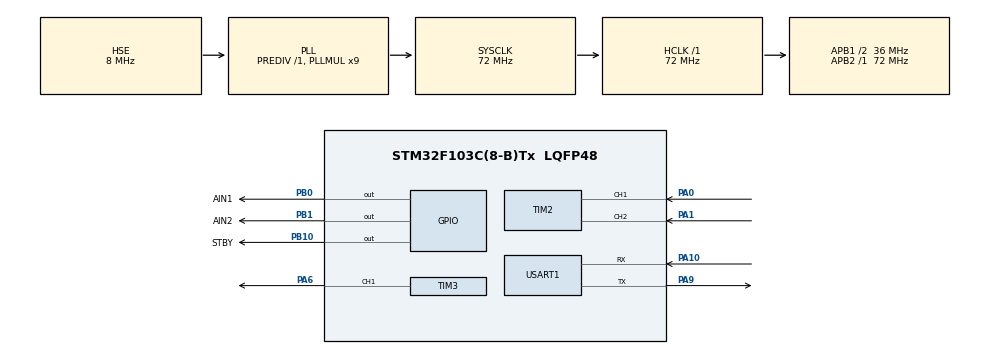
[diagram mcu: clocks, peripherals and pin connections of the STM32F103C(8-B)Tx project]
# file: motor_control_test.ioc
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Mcu.Family=STM32F1
Mcu.Name=STM32F103C(8-B)Tx
Mcu.Package=LQFP48
NVIC.PriorityGroup=NVIC_PRIORITYGROUP_4
PA0-WKUP.Signal=S_TIM2_CH1_ETR
PA1.Signal=S_TIM2_CH2
PA10.Mode=Asynchronous
PA10.Signal=USART1_RX
PA13.Mode=Serial_Wire
PA13.Signal=SYS_JTMS-SWDIO
PA14.Mode=Serial_Wire
PA14.Signal=SYS_JTCK-SWCLK
PA6.Signal=S_TIM3_CH1
PA9.Mode=Asynchronous
PA9.Signal=USART1_TX
PB0.GPIO_Label=AIN1
PB0.Signal=GPIO_Output
PB1.GPIO_Label=AIN2
PB1.Signal=GPIO_Output
PB10.GPIO_Label=STBY
PB10.Signal=GPIO_Output
PD0-OSC_IN.Mode=HSE-External-Oscillator
PD0-OSC_IN.Signal=RCC_OSC_IN
PD1-OSC_OUT.Mode=HSE-External-Oscillator
PD1-OSC_OUT.Signal=RCC_OSC_OUT
ProjectManager.HeapSize=0x200
ProjectManager.StackSize=0x400
ProjectManager.TargetToolchain=CMake
RCC.AHBFreq_Value=72000000
RCC.APB1CLKDivider=RCC_HCLK_DIV2
RCC.APB1Freq_Value=36000000
RCC.APB1TimFreq_Value=72000000
RCC.APB2Freq_Value=72000000
RCC.APB2TimFreq_Value=72000000
RCC.HCLKFreq_Value=72000000
RCC.PLLMUL=RCC_PLL_MUL9
RCC.PLLSourceVirtual=RCC_PLLSOURCE_HSE
RCC.SYSCLKFreq_VALUE=72000000
RCC.SYSCLKSource=RCC_SYSCLKSOURCE_PLLCLK
RCC.USBFreq_Value=72000000
SH.S_TIM2_CH1_ETR.0=TIM2_CH1,Encoder_Interface
SH.S_TIM2_CH2.0=TIM2_CH2,Encoder_Interface
SH.S_TIM3_CH1.0=TIM3_CH1,PWM Generation1 CH1
TIM2.EncoderMode=TIM_ENCODERMODE_TI2
TIM2.IC1Filter=10
TIM2.IC2Filter=10
TIM3.Channel-PWM\ Generation1\ CH1=TIM_CHANNEL_1
TIM3.Period=999
TIM3.Prescaler=71
USART1.VirtualMode=VM_ASYNC
VP_TIM3_VS_ClockSourceINT.Mode=Internal
board=custom

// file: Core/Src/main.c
/* USER CODE BEGIN Header */
/**
  ******************************************************************************
  * @file           : main.c
  * @brief          : Main program body
  ******************************************************************************
  * @attention
  *
  * Copyright (c) 2026 STMicroelectronics.
  * All rights reserved.
  *
  * This software is licensed under terms that can be found in the LICENSE file
  * in the root directory of this software component.
  * If no LICENSE file comes with this software, it is provided AS-IS.
  *
  ******************************************************************************
  */
/* USER CODE END Header */
#include "main.h"

#include <stdio.h>

#include "tim.h"
#include "usart.h"
#include "gpio.h"

/* USER CODE BEGIN PV */
 int16_t last_cnt = 0;

int16_t now_cnt;
int16_t delta;
/* USER CODE BEGIN PV */
int16_t  speed       = 0;    // 当前速度 (RPM)
uint8_t  pwm         = 0;    // PWM占空比 (0-100)
int16_t  targetSpeed = 1500; // 目标速度 (RPM)
uint32_t counter     = 0;    // 计数器值
char buf[20];               // sprintf格式化缓冲
/* USER CODE END PV */

void SystemClock_Config(void);

/* USER CODE BEGIN 0 */
/* USER CODE BEGIN 0 */

/* USER CODE END 0 */

int main(void)
{

  /* MCU Configuration--------------------------------------------------------*/

  /* Reset of all peripherals, Initializes the Flash interface and the Systick. */
  HAL_Init();

  /* Configure the system clock */
  SystemClock_Config();

  /* Initialize all configured peripherals */
  MX_GPIO_Init();
  MX_TIM2_Init();
  MX_TIM3_Init();
  MX_USART1_UART_Init();

  /* Infinite loop */
  while (1)
  {

  }
}

void SystemClock_Config(void)
{
  RCC_OscInitTypeDef RCC_OscInitStruct = {0};
  RCC_ClkInitTypeDef RCC_ClkInitStruct = {0};

  /** Initializes the RCC Oscillators according to the specified parameters
  * in the RCC_OscInitTypeDef structure.
  */
  RCC_OscInitStruct.OscillatorType = RCC_OSCILLATORTYPE_HSE;
  RCC_OscInitStruct.HSEState = RCC_HSE_ON;
  RCC_OscInitStruct.HSEPredivValue = RCC_HSE_PREDIV_DIV1;
  RCC_OscInitStruct.HSIState = RCC_HSI_ON;
  RCC_OscInitStruct.PLL.PLLState = RCC_PLL_ON;
  RCC_OscInitStruct.PLL.PLLSource = RCC_PLLSOURCE_HSE;
  RCC_OscInitStruct.PLL.PLLMUL = RCC_PLL_MUL9;
  if (HAL_RCC_OscConfig(&RCC_OscInitStruct) != HAL_OK)
  {
    Error_Handler();
  }

  /** Initializes the CPU, AHB and APB buses clocks
  */
  RCC_ClkInitStruct.ClockType = RCC_CLOCKTYPE_HCLK|RCC_CLOCKTYPE_SYSCLK
                              |RCC_CLOCKTYPE_PCLK1|RCC_CLOCKTYPE_PCLK2;
  RCC_ClkInitStruct.SYSCLKSource = RCC_SYSCLKSOURCE_PLLCLK;
  RCC_ClkInitStruct.AHBCLKDivider = RCC_SYSCLK_DIV1;
  RCC_ClkInitStruct.APB1CLKDivider = RCC_HCLK_DIV2;
  RCC_ClkInitStruct.APB2CLKDivider = RCC_HCLK_DIV1;

  if (HAL_RCC_ClockConfig(&RCC_ClkInitStruct, FLASH_LATENCY_2) != HAL_OK)
  {
    Error_Handler();
  }
}

void Error_Handler(void)
{
  __disable_irq();
  while (1)
  {
  }
}
